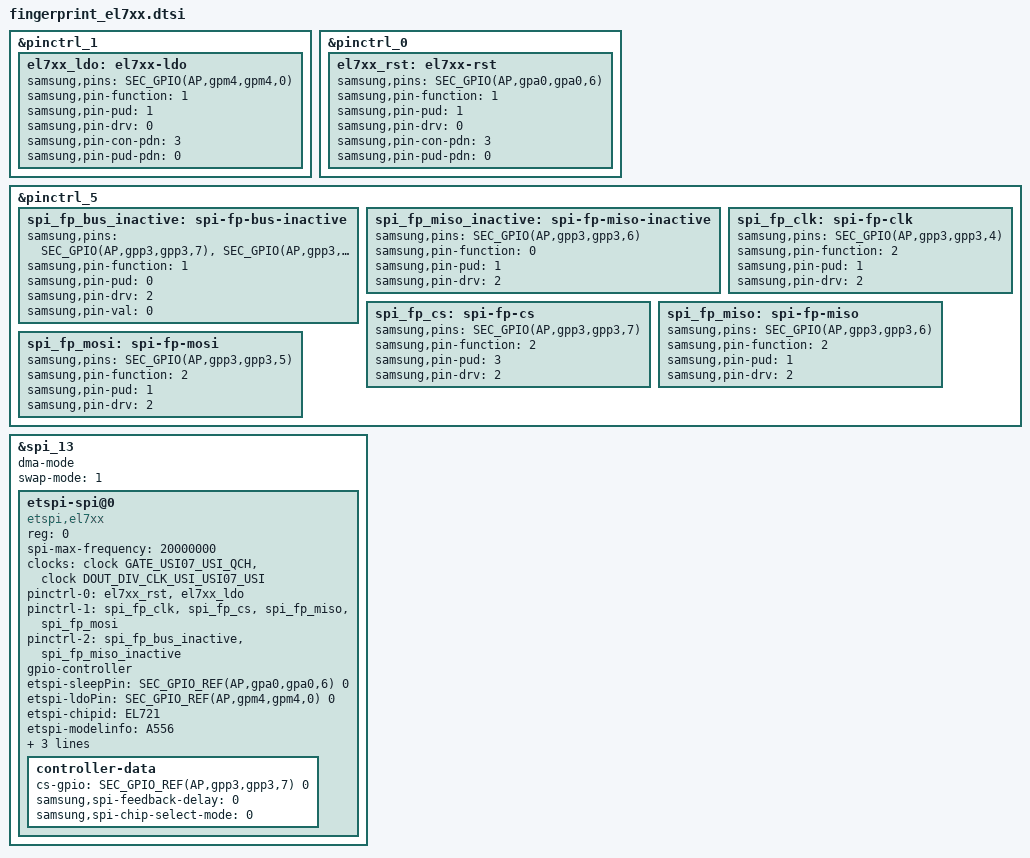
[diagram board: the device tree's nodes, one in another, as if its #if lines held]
/*
 * SAMSUNG EXYNOS9610 board device tree source
 *
 * Copyright (c) 2018 Samsung Electronics Co., Ltd.
 *		http://www.samsung.com
 *
 * This program is free software; you can redistribute it and/or modify
 * it under the terms of the GNU General Public License version 2 as
 * published by the Free Software Foundation.
 */

#if 1
&pinctrl_1 {
	el7xx_ldo: el7xx-ldo {
		samsung,pins = SEC_GPIO(AP,gpm4,gpm4,0);
		samsung,pin-function = <1>;
		samsung,pin-pud = <1>;
		samsung,pin-drv = <0>;
		samsung,pin-con-pdn = <3>;
		samsung,pin-pud-pdn = <0>;
	};
};
#endif

&pinctrl_0 {
	el7xx_rst: el7xx-rst {
		samsung,pins = SEC_GPIO(AP,gpa0,gpa0,6);
		samsung,pin-function = <1>;
		samsung,pin-pud = <1>;
		samsung,pin-drv = <0>;
		samsung,pin-con-pdn = <3>;
		samsung,pin-pud-pdn = <0>;
	};
};

&pinctrl_5 {
	/* SPI_FP */
	spi_fp_bus_inactive: spi-fp-bus-inactive {
		samsung,pins = SEC_GPIO(AP,gpp3,gpp3,7), SEC_GPIO(AP,gpp3,gpp3,4), SEC_GPIO(AP,gpp3,gpp3,5);
		samsung,pin-function = <1>;
		samsung,pin-pud = <0>;
		samsung,pin-drv = <2>;
		samsung,pin-val = <0>;
	};

	spi_fp_miso_inactive: spi-fp-miso-inactive {
		samsung,pins = SEC_GPIO(AP,gpp3,gpp3,6);
		samsung,pin-function = <0>;
		samsung,pin-pud = <1>;
		samsung,pin-drv = <2>;
	};

	spi_fp_clk: spi-fp-clk {
		samsung,pins = SEC_GPIO(AP,gpp3,gpp3,4);
		samsung,pin-function = <2>;
		samsung,pin-pud = <1>;
		samsung,pin-drv = <2>;
	};

	spi_fp_cs: spi-fp-cs {
		samsung,pins = SEC_GPIO(AP,gpp3,gpp3,7);
		samsung,pin-function = <2>;
		samsung,pin-pud = <3>;
		samsung,pin-drv = <2>;
	};

	spi_fp_miso: spi-fp-miso {
		samsung,pins = SEC_GPIO(AP,gpp3,gpp3,6);
		samsung,pin-function = <2>;
		samsung,pin-pud = <1>;
		samsung,pin-drv = <2>;
	};

	spi_fp_mosi: spi-fp-mosi {
		samsung,pins = SEC_GPIO(AP,gpp3,gpp3,5);
		samsung,pin-function = <2>;
		samsung,pin-pud = <1>;
		samsung,pin-drv = <2>;
	};
};

#if defined(CONFIG_SEC_FACTORY) || !1
&spi_13 {
	status = "okay";
	pinctrl-names = "";
	dma-mode;
	swap-mode = <1>;
#else
&smd {
#endif
	etspi-spi@0 {
		compatible = "etspi,el7xx";
		reg = <0>;
		spi-max-frequency = <20000000>;
#if !defined(CONFIG_SEC_FACTORY) && 1
		clocks = <&clock GATE_USI07_USI_QCH>, <&clock DOUT_DIV_CLK_USI_USI07_USI>;
		clock-names = "gate_spi_clk", "ipclk_spi";
#endif

		pinctrl-names = "default", "pins_poweron", "pins_poweroff";
#if 1
		pinctrl-0 = <&el7xx_rst &el7xx_ldo>;
#else
		pinctrl-0 = <&el7xx_rst>;
#endif
		pinctrl-1 = <&spi_fp_clk &spi_fp_cs &spi_fp_miso &spi_fp_mosi>;
		pinctrl-2 = <&spi_fp_bus_inactive &spi_fp_miso_inactive>;

		gpio-controller;
		#gpio-cells = <2>;

		etspi-sleepPin = <SEC_GPIO_REF(AP,gpa0,gpa0,6) 0>;
#if 1
		etspi-ldoPin = <SEC_GPIO_REF(AP,gpm4,gpm4,0) 0>;
#endif
#if 0
		etspi-regulator = "VDD_BTP_3P3";
#endif
		etspi-chipid = "EL721";
		etspi-modelinfo = "A556";
		etspi-position = "12.20,0.00,9.10,9.10,14.80,14.80,12.00,12.00,5.00";
		etspi-rb = "647,-1,-1,FFFFFF";
		controller-data {
			cs-gpio = <SEC_GPIO_REF(AP,gpp3,gpp3,7) 0>;
			samsung,spi-feedback-delay = <0>;
			samsung,spi-chip-select-mode = <0>;
		};
	};
};

#if 0
&${fps_regul_vdd_3p3} {
	regulator-name = "VDD_BTP_3P3";
	regulator-ramp-delay = <12000>;
};
#endif

